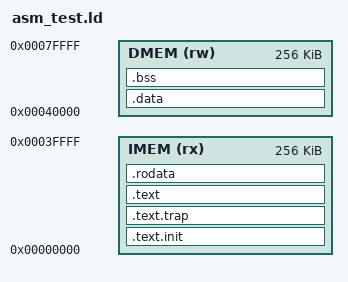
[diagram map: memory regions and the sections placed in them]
/*==============================================================================
 * asm_test.ld — RV32I 教学 core 汇编测试链接脚本
 *
 * 内存布局：
 *   IMEM (0x00000000) : .text
 *   DMEM (0x00040000) : .data / .bss
 *
 * 当前 simple_rom/simple_ram 默认 ADDR_WIDTH=16，即 65536 个 32-bit word，
 * 每块 memory 容量为 256 KiB。链接脚本与这个仿真 memory model 保持一致。
 *
 * 用法：
 *   ${CROSS_COMPILE}ld -T sw/linker/asm_test.ld -o program.elf program.o
 *============================================================================*/

OUTPUT_ARCH(riscv)
ENTRY(_start)

MEMORY
{
    /* 指令存储器：起始地址 0x00000000，256 KiB */
    IMEM (rx)  : ORIGIN = 0x00000000, LENGTH = 256K

    /* 数据存储器：起始地址 0x00040000，256 KiB */
    DMEM (rw)  : ORIGIN = 0x00040000, LENGTH = 256K
}

SECTIONS
{
    __trap_vector = ORIGIN(IMEM) + 0x80;

    /*----------------------------------------------------------------------
     * .text.init — reset 后执行的入口 stub，必须位于 IMEM 起始地址。
     *--------------------------------------------------------------------*/
    .text.init : ALIGN(4)
    {
        KEEP(*(.text.init))
    } > IMEM

    ASSERT(. <= __trap_vector, ".text.init overlaps trap vector")

    /*----------------------------------------------------------------------
     * .text.trap — M-mode direct trap 入口，和 core_pkg::MTVEC_RESET 对齐。
     *--------------------------------------------------------------------*/
    .text.trap __trap_vector : ALIGN(4)
    {
        __trap_section_start = .;
        KEEP(*(.text.trap))
        . = MAX(., __trap_section_start + 4);
    } > IMEM

    /*----------------------------------------------------------------------
     * .text — 普通代码段，放在 trap vector 之后。
     *--------------------------------------------------------------------*/
    .text : ALIGN(4)
    {
        *(.text)
        *(.text.*)
    } > IMEM

    /*----------------------------------------------------------------------
     * .rodata — 只读数据，可以放 IMEM 或 DMEM，这里放 IMEM
     *--------------------------------------------------------------------*/
    .rodata : ALIGN(4)
    {
        *(.rodata)
        *(.rodata.*)
    } > IMEM

    /*----------------------------------------------------------------------
     * .data — 已初始化全局/静态数据，放在 DMEM
     *--------------------------------------------------------------------*/
    .data : ALIGN(4)
    {
        __data_start = .;
        *(.data)
        *(.data.*)
        __data_end = .;
    } > DMEM

    /*----------------------------------------------------------------------
     * .bss — 未初始化全局/静态数据，放在 DMEM
     *--------------------------------------------------------------------*/
    .bss : ALIGN(4)
    {
        __bss_start = .;
        *(.bss)
        *(.bss.*)
        *(COMMON)
        __bss_end = .;
    } > DMEM

    /*----------------------------------------------------------------------
     * 堆栈指针初始化：_sp = DMEM 末尾（向下生长）
     *--------------------------------------------------------------------*/
    __sp = ORIGIN(DMEM) + LENGTH(DMEM);
}
